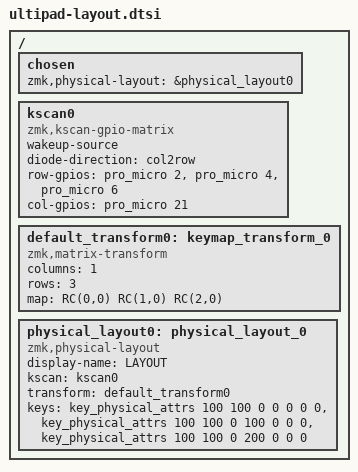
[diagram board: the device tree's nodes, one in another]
/*
 * Copyright (c) 2024 The ZMK Contributors
 *
 * SPDX-License-Identifier: MIT
 */

#include <physical_layouts.dtsi>

/ {
    chosen {
        zmk,physical-layout = &physical_layout0;
    };

    kscan0: kscan0 {
        compatible = "zmk,kscan-gpio-matrix";
        wakeup-source;

        diode-direction = "col2row";
        row-gpios
            = <&pro_micro 2 (GPIO_ACTIVE_HIGH | GPIO_PULL_DOWN)>
            , <&pro_micro 4 (GPIO_ACTIVE_HIGH | GPIO_PULL_DOWN)>
            , <&pro_micro 6 (GPIO_ACTIVE_HIGH | GPIO_PULL_DOWN)>
            ;
        col-gpios
            = <&pro_micro 21 GPIO_ACTIVE_HIGH>
            ;
    };

    default_transform0: keymap_transform_0 {
        compatible = "zmk,matrix-transform";
        columns = <1>;
        rows = <3>;
        map = <
            RC(0,0)
            RC(1,0)
            RC(2,0)
        >;
    };

    physical_layout0: physical_layout_0 {
        compatible = "zmk,physical-layout";
        display-name = "LAYOUT";

        kscan = <&kscan0>;
        transform = <&default_transform0>;

        keys  //                     w   h    x    y     rot    rx    ry
            = <&key_physical_attrs 100 100    0    0       0     0     0>
            , <&key_physical_attrs 100 100    0  100       0     0     0>
            , <&key_physical_attrs 100 100    0  200       0     0     0>
            ;
    };
};
